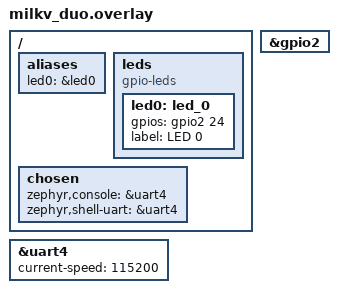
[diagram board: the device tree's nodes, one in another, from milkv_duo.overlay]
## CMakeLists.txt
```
# Copyright (c) 2024 GP Orcullo
# SPDX-License-Identifier: Apache-2.0

cmake_minimum_required(VERSION 3.20.0)

set(BOARD milkv_duo)

list(APPEND BOARD_ROOT ${CMAKE_CURRENT_SOURCE_DIR}/..)
list(APPEND SOC_ROOT ${CMAKE_CURRENT_SOURCE_DIR}/..)
list(APPEND DTS_ROOT ${CMAKE_CURRENT_SOURCE_DIR}/..)
list(APPEND ZEPHYR_EXTRA_MODULES ${CMAKE_CURRENT_SOURCE_DIR}/../drivers)

find_package(Zephyr REQUIRED HINTS $ENV{ZEPHYR_BASE})

project(blinky)

target_sources(app PRIVATE src/main.c)
```

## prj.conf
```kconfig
CONFIG_GPIO=y
# CONFIG_SERIAL=n
# CONFIG_CONSOLE=n
# CONFIG_UART_CONSOLE=n
# CONFIG_STDOUT_CONSOLE=n
# CONFIG_PRINTK=n
# CONFIG_EARLY_CONSOLE=n
```

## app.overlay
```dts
/ {
	aliases {
		led0 = &led0;
	};

	leds {
		compatible = "gpio-leds";
		led0: led_0 {
			gpios = <&gpio2 24 0>;
			label = "LED 0";
		};
        };
};
```

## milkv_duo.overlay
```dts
/ {
	aliases {
		led0 = &led0;
	};

	leds {
		compatible = "gpio-leds";
		led0: led_0 {
			gpios = <&gpio2 24 0>;
			label = "LED 0";
		};
        };

        chosen {
                zephyr,console = &uart4;
                zephyr,shell-uart = &uart4;
        };
};

&uart4 {
        status = "okay";
        current-speed = <115200>;
};

&gpio2 {
	status = "okay";
};
```

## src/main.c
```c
/*
 * Copyright (c) 2016 Intel Corporation
 *
 * SPDX-License-Identifier: Apache-2.0
 */

#include <stdio.h>
#include <zephyr/kernel.h>
#include <zephyr/drivers/gpio.h>

/* 1000 msec = 1 sec */
#define SLEEP_TIME_MS   1000

/* The devicetree node identifier for the "led0" alias. */
#define LED0_NODE DT_ALIAS(led0)

/*
 * A build error on this line means your board is unsupported.
 * See the sample documentation for information on how to fix this.
 */
static const struct gpio_dt_spec led = GPIO_DT_SPEC_GET(LED0_NODE, gpios);

int main(void)
{
	int ret;
	bool led_state = true;

	if (!gpio_is_ready_dt(&led)) {
		return 0;
	}

	ret = gpio_pin_configure_dt(&led, GPIO_OUTPUT_ACTIVE);
	if (ret < 0) {
		return 0;
	}

	while (1) {
		ret = gpio_pin_toggle_dt(&led);
		if (ret < 0) {
			return 0;
		}

		led_state = !led_state;
		printf("LED state: %s\n", led_state ? "ON" : "OFF");

		if (led_state) {
                    k_msleep(SLEEP_TIME_MS);
                } else {
                    k_msleep(SLEEP_TIME_MS/2);
                }

	}
	return 0;
}
```
